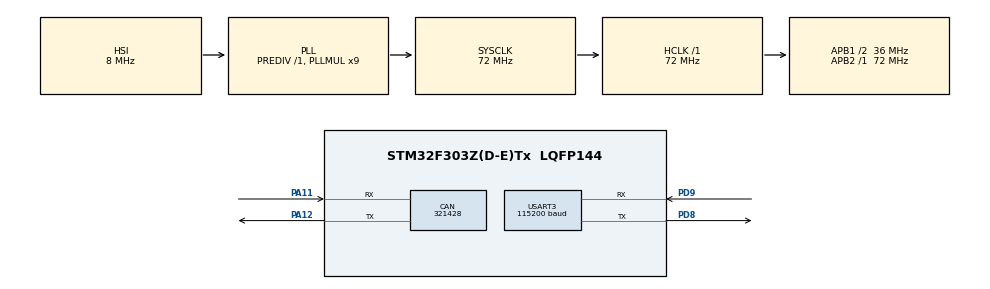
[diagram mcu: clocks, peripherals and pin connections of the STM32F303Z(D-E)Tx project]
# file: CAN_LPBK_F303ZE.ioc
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CAN.BS1=CAN_BS1_4TQ
CAN.BS2=CAN_BS2_2TQ
CAN.CalculateBaudRate=321428
CAN.CalculateTimeBit=3111.11
CAN.CalculateTimeQuantum=444.44444444444446
Mcu.Family=STM32F3
Mcu.Name=STM32F303Z(D-E)Tx
Mcu.Package=LQFP144
NVIC.PriorityGroup=NVIC_PRIORITYGROUP_4
NVIC.USB_LP_CAN_RX0_IRQn=true\:0\:0\:false\:false\:true\:true\:true
PA11.Mode=CAN_Activate
PA11.Signal=CAN_RX
PA12.Mode=CAN_Activate
PA12.Signal=CAN_TX
PD8.Mode=Asynchronous
PD8.Signal=USART3_TX
PD9.Mode=Asynchronous
PD9.Signal=USART3_RX
ProjectManager.HeapSize=0x200
ProjectManager.StackSize=0x400
ProjectManager.TargetToolchain=STM32CubeIDE
RCC.AHBFreq_Value=72000000
RCC.APB1CLKDivider=RCC_HCLK_DIV2
RCC.APB1Freq_Value=36000000
RCC.APB1TimFreq_Value=72000000
RCC.APB2Freq_Value=72000000
RCC.APB2TimFreq_Value=72000000
RCC.CortexFreq_Value=72000000
RCC.HCLKFreq_Value=72000000
RCC.HSE_VALUE=8000000
RCC.HSI_VALUE=8000000
RCC.LSE_VALUE=32768
RCC.PLLMUL=RCC_PLL_MUL9
RCC.SYSCLKFreq_VALUE=72000000
RCC.SYSCLKSourceVirtual=RCC_SYSCLKSOURCE_PLLCLK
RCC.USBFreq_Value=72000000
USART3.BaudRate=115200
USART3.VirtualMode-Asynchronous=VM_ASYNC
board=custom

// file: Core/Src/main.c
/* USER CODE BEGIN Header */
/**
 ******************************************************************************
 * @file           : main.c
 * @brief          : Main program body
 ******************************************************************************
 * @attention
 *
 * <h2><center>&copy; Copyright (c) 2021 STMicroelectronics.
 * All rights reserved.</center></h2>
 *
 * This software component is licensed by ST under BSD 3-Clause license,
 * the "License"; You may not use this file except in compliance with the
 * License. You may obtain a copy of the License at:
 *                        opensource.org/licenses/BSD-3-Clause
 *
 ******************************************************************************
 */
/* USER CODE END Header */
#include "main.h"

CAN_HandleTypeDef hcan;

UART_HandleTypeDef huart3;

/* USER CODE BEGIN PV */
static CAN_RxHeaderTypeDef RxMsg;
uint8_t * CAN_RX_DATA;
//static CAN_TxHeaderTypeDef TxMsg;
/* USER CODE END PV */

void SystemClock_Config(void);
static void MX_GPIO_Init(void);
static void MX_CAN_Init(void);
static void MX_USART3_UART_Init(void);

int main(void)
{

  /* MCU Configuration--------------------------------------------------------*/

  /* Reset of all peripherals, Initializes the Flash interface and the Systick. */
  HAL_Init();

  /* Configure the system clock */
  SystemClock_Config();

  /* Initialize all configured peripherals */
  MX_GPIO_Init();
  MX_CAN_Init();
  MX_USART3_UART_Init();
  /* USER CODE BEGIN 2 */
	printMsg("CAN Analyzer\r\n");
	printMsg("Built on: %s %s\r\n", __DATE__, __TIME__);
	printMsg("Engineer: Aditya Sehgal\r\n");
  /* USER CODE END 2 */

  /* Infinite loop */
	while (1)
	{

    /* USER CODE BEGIN 3 */
		HAL_CAN_GetRxMessage(&hcan, 128, &RxMsg, CAN_RX_DATA);
	}
  /* USER CODE END 3 */
}

void SystemClock_Config(void)
{
  RCC_OscInitTypeDef RCC_OscInitStruct = {0};
  RCC_ClkInitTypeDef RCC_ClkInitStruct = {0};
  RCC_PeriphCLKInitTypeDef PeriphClkInit = {0};

  /** Initializes the RCC Oscillators according to the specified parameters
  * in the RCC_OscInitTypeDef structure.
  */
  RCC_OscInitStruct.OscillatorType = RCC_OSCILLATORTYPE_HSI;
  RCC_OscInitStruct.HSIState = RCC_HSI_ON;
  RCC_OscInitStruct.HSICalibrationValue = RCC_HSICALIBRATION_DEFAULT;
  RCC_OscInitStruct.PLL.PLLState = RCC_PLL_ON;
  RCC_OscInitStruct.PLL.PLLSource = RCC_PLLSOURCE_HSI;
  RCC_OscInitStruct.PLL.PLLMUL = RCC_PLL_MUL9;
  RCC_OscInitStruct.PLL.PREDIV = RCC_PREDIV_DIV1;
  if (HAL_RCC_OscConfig(&RCC_OscInitStruct) != HAL_OK)
  {
    Error_Handler();
  }
  /** Initializes the CPU, AHB and APB buses clocks
  */
  RCC_ClkInitStruct.ClockType = RCC_CLOCKTYPE_HCLK|RCC_CLOCKTYPE_SYSCLK
                              |RCC_CLOCKTYPE_PCLK1|RCC_CLOCKTYPE_PCLK2;
  RCC_ClkInitStruct.SYSCLKSource = RCC_SYSCLKSOURCE_PLLCLK;
  RCC_ClkInitStruct.AHBCLKDivider = RCC_SYSCLK_DIV1;
  RCC_ClkInitStruct.APB1CLKDivider = RCC_HCLK_DIV2;
  RCC_ClkInitStruct.APB2CLKDivider = RCC_HCLK_DIV1;

  if (HAL_RCC_ClockConfig(&RCC_ClkInitStruct, FLASH_LATENCY_2) != HAL_OK)
  {
    Error_Handler();
  }
  PeriphClkInit.PeriphClockSelection = RCC_PERIPHCLK_USART3;
  PeriphClkInit.Usart3ClockSelection = RCC_USART3CLKSOURCE_PCLK1;
  if (HAL_RCCEx_PeriphCLKConfig(&PeriphClkInit) != HAL_OK)
  {
    Error_Handler();
  }
}

static void MX_CAN_Init(void)
{

  hcan.Instance = CAN;
  hcan.Init.Prescaler = 16;
  hcan.Init.Mode = CAN_MODE_NORMAL;
  hcan.Init.SyncJumpWidth = CAN_SJW_1TQ;
  hcan.Init.TimeSeg1 = CAN_BS1_4TQ;
  hcan.Init.TimeSeg2 = CAN_BS2_2TQ;
  hcan.Init.TimeTriggeredMode = DISABLE;
  hcan.Init.AutoBusOff = DISABLE;
  hcan.Init.AutoWakeUp = DISABLE;
  hcan.Init.AutoRetransmission = DISABLE;
  hcan.Init.ReceiveFifoLocked = DISABLE;
  hcan.Init.TransmitFifoPriority = DISABLE;
  if (HAL_CAN_Init(&hcan) != HAL_OK)
  {
    Error_Handler();
  }

}

static void MX_USART3_UART_Init(void)
{

  huart3.Instance = USART3;
  huart3.Init.BaudRate = 115200;
  huart3.Init.WordLength = UART_WORDLENGTH_8B;
  huart3.Init.StopBits = UART_STOPBITS_1;
  huart3.Init.Parity = UART_PARITY_NONE;
  huart3.Init.Mode = UART_MODE_TX_RX;
  huart3.Init.HwFlowCtl = UART_HWCONTROL_NONE;
  huart3.Init.OverSampling = UART_OVERSAMPLING_16;
  huart3.Init.OneBitSampling = UART_ONE_BIT_SAMPLE_DISABLE;
  huart3.AdvancedInit.AdvFeatureInit = UART_ADVFEATURE_NO_INIT;
  if (HAL_UART_Init(&huart3) != HAL_OK)
  {
    Error_Handler();
  }

}

static void MX_GPIO_Init(void)
{

  /* GPIO Ports Clock Enable */
  __HAL_RCC_GPIOD_CLK_ENABLE();
  __HAL_RCC_GPIOA_CLK_ENABLE();

}

/* USER CODE BEGIN 4 */
void printMsg(char *format, ...)
{
	char str[80];

	/*Extract the the argument list using VA apis */
	va_list args;
	va_start(args, format);
	vsprintf(str, format, args);
	HAL_UART_Transmit(&huart3, (uint8_t*) str, strlen(str), HAL_MAX_DELAY);
	va_end(args);
}
/* USER CODE END 4 */

void Error_Handler(void)
{
	__disable_irq();
	while (1)
	{
	}
}

/************************ (C) COPYRIGHT STMicroelectronics *****END OF FILE****/
